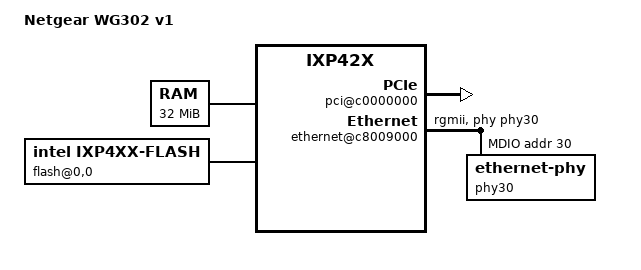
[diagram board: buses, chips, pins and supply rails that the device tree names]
/dts-v1/;
#include "intel-ixp42x.dtsi"
#include <dt-bindings/input/input.h>
/ {
	model = "Netgear WG302 v1";
	compatible = "netgear,wg302v1", "intel,ixp42x";
	#address-cells = <1>;
	#size-cells = <1>;
	memory@0 {
		device_type = "memory";
		reg = <0x00000000 0x02000000>;
	};
	chosen {
		bootargs = "console=ttyS0,9600n8";
		stdout-path = "uart1:9600n8";
	};
	aliases {
		serial0 = &uart1;
	};
	soc {
		bus@c4000000 {
			flash@0,0 {
				compatible = "intel,ixp4xx-flash", "cfi-flash";
				bank-width = <2>;
				reg = <0 0x00000000 0x800000>;
				intel,ixp4xx-eb-write-enable = <1>;
				partitions {
					compatible = "redboot-fis";
					fis-index-block = <0x3f>;
				};
			};
		};
		pci@c0000000 {
			status = "okay";
			#interrupt-cells = <1>;
			interrupt-map-mask = <0xf800 0 0 7>;
			interrupt-map =
			<0x0800 0 0 1 &gpio0 8 IRQ_TYPE_LEVEL_LOW>,  
			<0x0800 0 0 2 &gpio0 8 IRQ_TYPE_LEVEL_LOW>,  
			<0x0800 0 0 3 &gpio0 8 IRQ_TYPE_LEVEL_LOW>,  
			<0x0800 0 0 4 &gpio0 8 IRQ_TYPE_LEVEL_LOW>,  
			<0x1000 0 0 1 &gpio0 9 IRQ_TYPE_LEVEL_LOW>,  
			<0x1000 0 0 2 &gpio0 9 IRQ_TYPE_LEVEL_LOW>,  
			<0x1000 0 0 3 &gpio0 9 IRQ_TYPE_LEVEL_LOW>,  
			<0x1000 0 0 4 &gpio0 9 IRQ_TYPE_LEVEL_LOW>;  
		};
		ethernet@c8009000 {
			status = "okay";
			queue-rx = <&qmgr 3>;
			queue-txready = <&qmgr 20>;
			phy-mode = "rgmii";
			phy-handle = <&phy30>;
			mdio {
				#address-cells = <1>;
				#size-cells = <0>;
				phy30: ethernet-phy@30 {
					reg = <30>;
				};
			};
		};
	};
};
